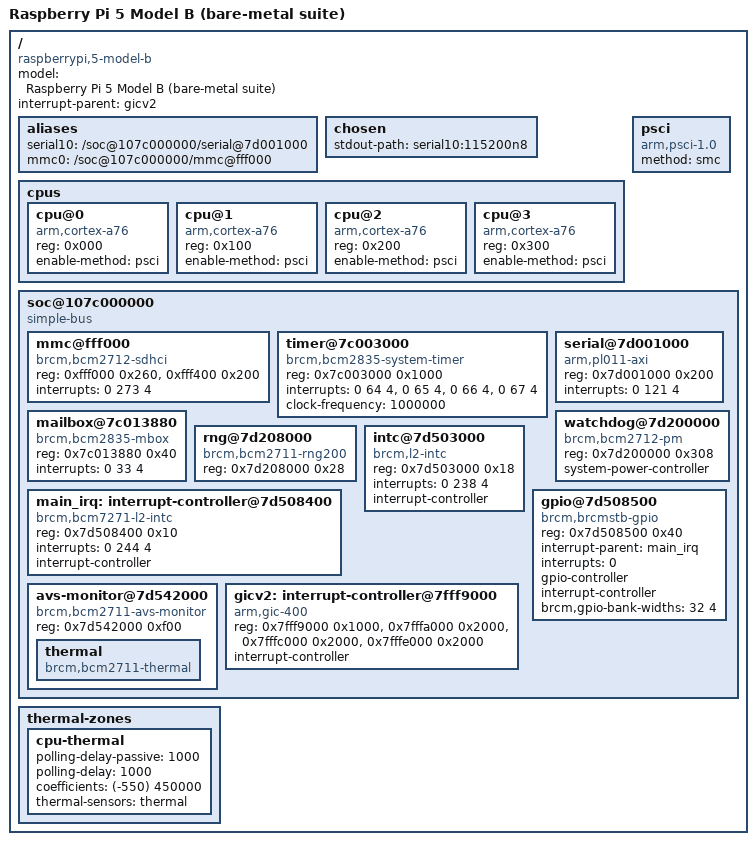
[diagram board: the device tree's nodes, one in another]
// SPDX-License-Identifier: GPL-2.0-or-later
//
// The parts of bcm2712-rpi-5-b.dtb the bare-metal suite looks up, with the
// same structure: devices under the "soc" simple-bus, whose "ranges" map
// bus address 0x0 to CPU address 0x10_0000_0000, and the console chosen
// through an alias. Used by test_suite.py for its -dtb runs.

/dts-v1/;

/ {
    compatible = "raspberrypi,5-model-b", "brcm,bcm2712";
    model = "Raspberry Pi 5 Model B (bare-metal suite)";
    #address-cells = <2>;
    #size-cells = <2>;
    interrupt-parent = <&gicv2>;

    aliases {
        serial10 = "/soc@107c000000/serial@7d001000";
        mmc0 = "/soc@107c000000/mmc@fff000";
    };

    chosen {
        stdout-path = "serial10:115200n8";
    };

    cpus {
        #address-cells = <1>;
        #size-cells = <0>;

        cpu@0 { device_type = "cpu"; compatible = "arm,cortex-a76";
                reg = <0x000>; enable-method = "psci"; };
        cpu@1 { device_type = "cpu"; compatible = "arm,cortex-a76";
                reg = <0x100>; enable-method = "psci"; };
        cpu@2 { device_type = "cpu"; compatible = "arm,cortex-a76";
                reg = <0x200>; enable-method = "psci"; };
        cpu@3 { device_type = "cpu"; compatible = "arm,cortex-a76";
                reg = <0x300>; enable-method = "psci"; };
    };

    psci {
        compatible = "arm,psci-1.0", "arm,psci-0.2";
        method = "smc";
    };

    soc@107c000000 {
        compatible = "simple-bus";
        #address-cells = <1>;
        #size-cells = <1>;
        ranges = <0x00000000  0x10 0x00000000  0x80000000>;

        mmc@fff000 {
            compatible = "brcm,bcm2712-sdhci", "brcm,sdhci-brcmstb";
            reg = <0xfff000 0x260>, <0xfff400 0x200>;
            reg-names = "host", "cfg";
            interrupts = <0 273 4>;
        };

        timer@7c003000 {
            compatible = "brcm,bcm2835-system-timer";
            reg = <0x7c003000 0x1000>;
            interrupts = <0 64 4>, <0 65 4>, <0 66 4>, <0 67 4>;
            clock-frequency = <1000000>;
        };

        serial@7d001000 {
            compatible = "arm,pl011-axi", "arm,pl011", "arm,primecell";
            reg = <0x7d001000 0x200>;
            interrupts = <0 121 4>;
        };

        mailbox@7c013880 {
            compatible = "brcm,bcm2835-mbox";
            reg = <0x7c013880 0x40>;
            interrupts = <0 33 4>;
            #mbox-cells = <0>;
        };

        watchdog@7d200000 {
            compatible = "brcm,bcm2712-pm";
            reg = <0x7d200000 0x308>;
            reg-names = "pm";
            system-power-controller;
        };

        rng@7d208000 {
            compatible = "brcm,bcm2711-rng200";
            reg = <0x7d208000 0x28>;
        };

        intc@7d503000 {
            compatible = "brcm,l2-intc";
            reg = <0x7d503000 0x18>;
            interrupts = <0 238 4>;
            interrupt-controller;
            #interrupt-cells = <1>;
        };

        main_irq: interrupt-controller@7d508400 {
            compatible = "brcm,bcm7271-l2-intc";
            reg = <0x7d508400 0x10>;
            interrupts = <0 244 4>;
            interrupt-controller;
            #interrupt-cells = <1>;
        };

        gpio@7d508500 {
            compatible = "brcm,brcmstb-gpio";
            reg = <0x7d508500 0x40>;
            interrupt-parent = <&main_irq>;
            interrupts = <0>;
            gpio-controller;
            #gpio-cells = <2>;
            interrupt-controller;
            #interrupt-cells = <2>;
            brcm,gpio-bank-widths = <32 4>;
        };

        avs-monitor@7d542000 {
            compatible = "brcm,bcm2711-avs-monitor", "syscon", "simple-mfd";
            reg = <0x7d542000 0xf00>;

            thermal: thermal {
                compatible = "brcm,bcm2711-thermal";
                #thermal-sensor-cells = <0>;
            };
        };

        gicv2: interrupt-controller@7fff9000 {
            compatible = "arm,gic-400";
            reg = <0x7fff9000 0x1000>,
                  <0x7fffa000 0x2000>,
                  <0x7fffc000 0x2000>,
                  <0x7fffe000 0x2000>;
            interrupt-controller;
            #interrupt-cells = <3>;
            #address-cells = <0>;
        };
    };

    thermal-zones {
        cpu-thermal {
            polling-delay-passive = <1000>;
            polling-delay = <1000>;
            coefficients = <(-550) 450000>;
            thermal-sensors = <&thermal>;
        };
    };
};
